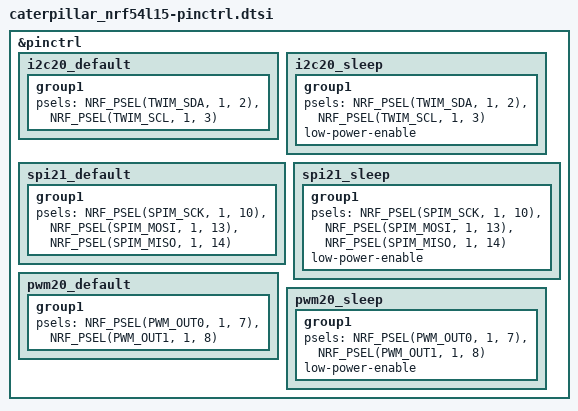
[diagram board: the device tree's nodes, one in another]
&pinctrl {
	i2c20_default: i2c20_default {
		group1 {
			psels = <NRF_PSEL(TWIM_SDA, 1, 2)>,
				    <NRF_PSEL(TWIM_SCL, 1, 3)>;
		};
	};

	i2c20_sleep: i2c20_sleep {
		group1 {
			psels = <NRF_PSEL(TWIM_SDA, 1, 2)>,
				    <NRF_PSEL(TWIM_SCL, 1, 3)>;
			low-power-enable;
		};
	};

	spi21_default: spi21_default {
		group1 {
			/* IMU (ASM330LHHTR): SCLK P1.10, MOSI→SDI P1.13, MISO←SDO P1.14.
			 * CS (P1.09) is a plain GPIO driven by the IMU driver.
			 */
			psels = <NRF_PSEL(SPIM_SCK, 1, 10)>,
				    <NRF_PSEL(SPIM_MOSI, 1, 13)>,
				    <NRF_PSEL(SPIM_MISO, 1, 14)>;
		};
	};

	spi21_sleep: spi21_sleep {
		group1 {
			psels = <NRF_PSEL(SPIM_SCK, 1, 10)>,
				    <NRF_PSEL(SPIM_MOSI, 1, 13)>,
				    <NRF_PSEL(SPIM_MISO, 1, 14)>;
			low-power-enable;
		};
	};

	pwm20_default: pwm20_default {
		group1 {
			/* PWM_OUT0 = IN1, PWM_OUT1 = IN2 */
			psels = <NRF_PSEL(PWM_OUT0, 1, 7)>,
				    <NRF_PSEL(PWM_OUT1, 1, 8)>;
		};
	};

	pwm20_sleep: pwm20_sleep {
		group1 {
			psels = <NRF_PSEL(PWM_OUT0, 1, 7)>,
				    <NRF_PSEL(PWM_OUT1, 1, 8)>;
			low-power-enable;
		};
	};
};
